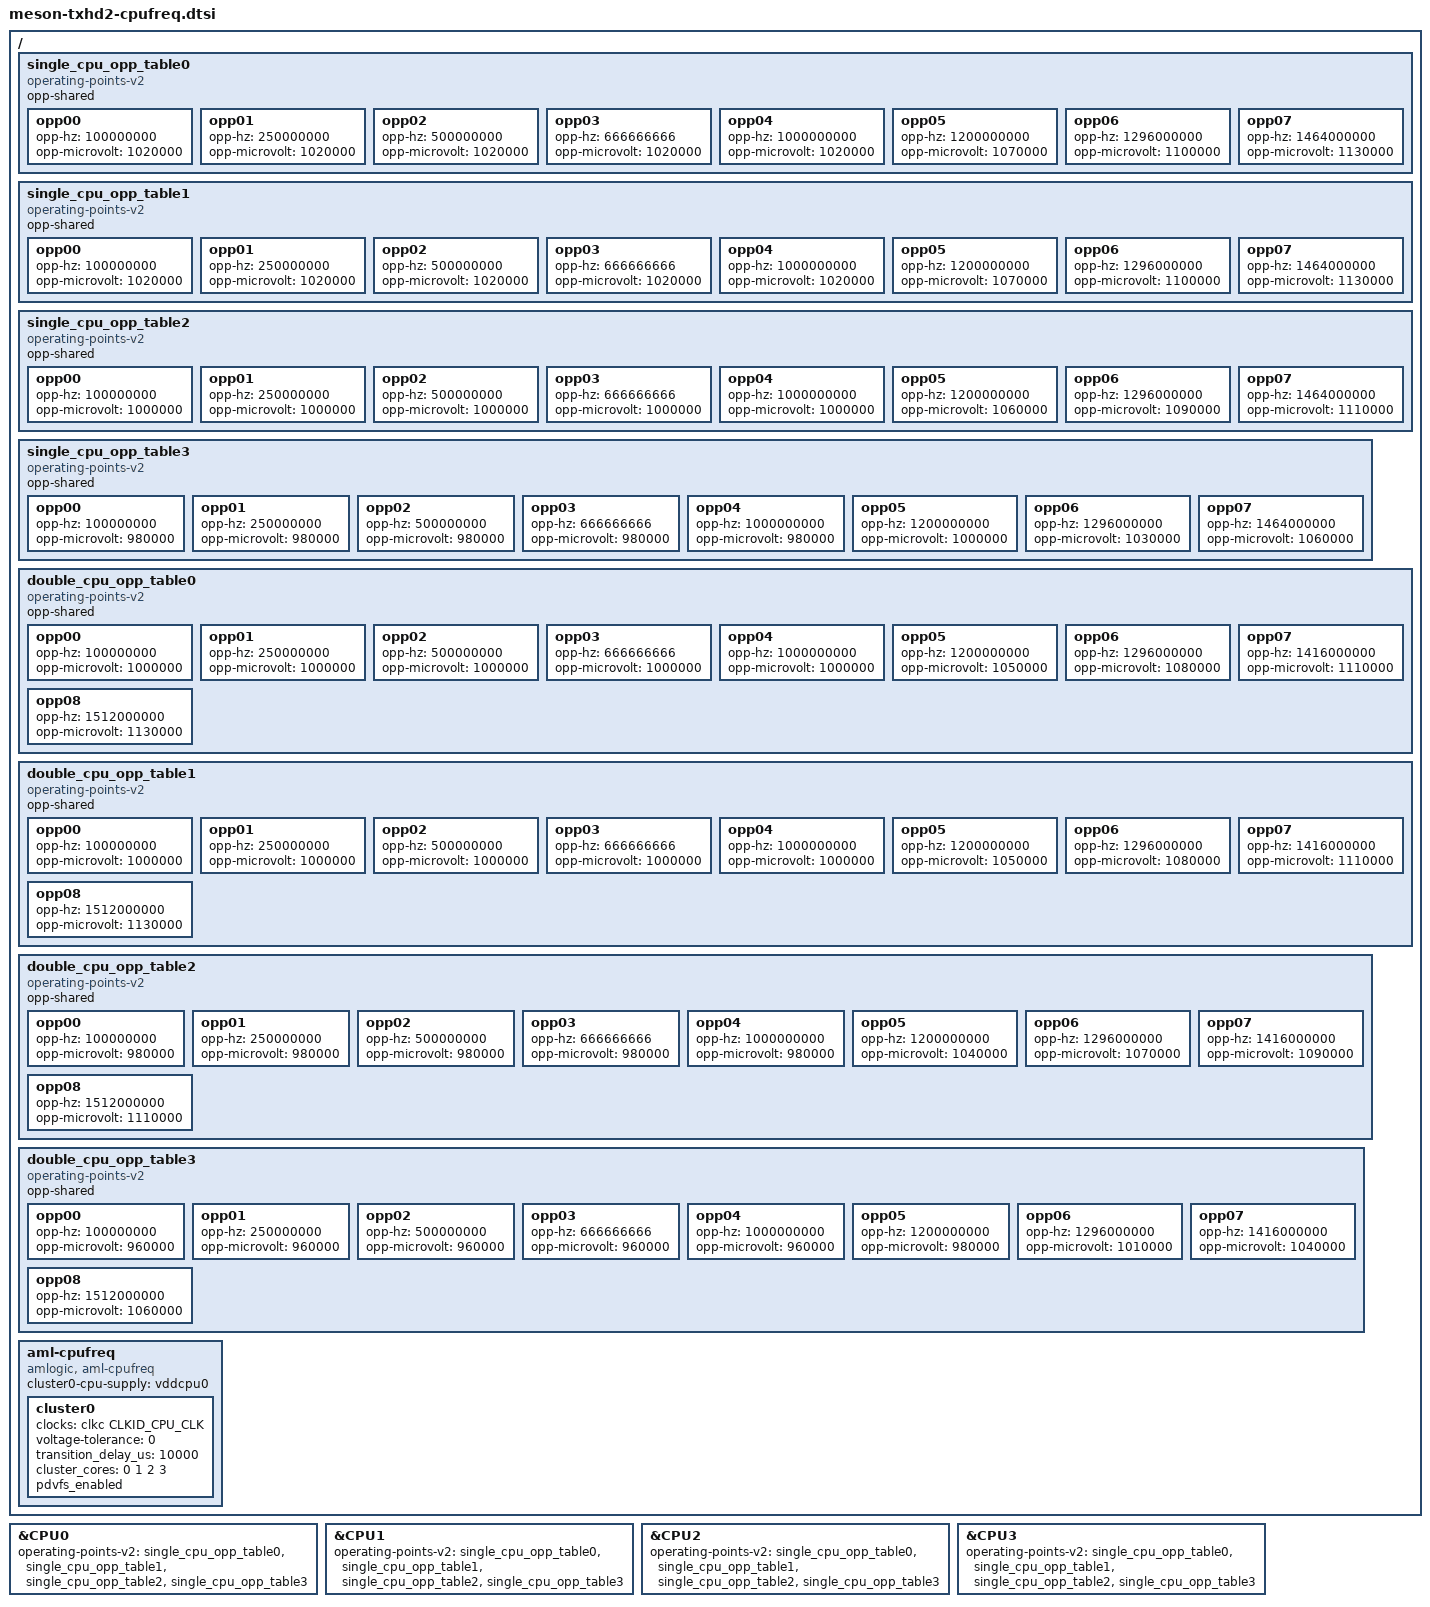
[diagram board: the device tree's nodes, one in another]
// SPDX-License-Identifier: (GPL-2.0+ OR MIT)
/*
 * Copyright (c) 2019 Amlogic, Inc. All rights reserved.
 */
/ {
	single_cpu_opp_table0: single_cpu_opp_table0 {
		compatible = "operating-points-v2";
		opp-shared;

		opp00 {
			opp-hz = /bits/ 64 <100000000>;
			opp-microvolt = <1020000>;
		};
		opp01 {
			opp-hz = /bits/ 64 <250000000>;
			opp-microvolt = <1020000>;
		};
		opp02 {
			opp-hz = /bits/ 64 <500000000>;
			opp-microvolt = <1020000>;
		};
		opp03 {
			opp-hz = /bits/ 64 <666666666>;
			opp-microvolt = <1020000>;
		};
		opp04 {
			opp-hz = /bits/ 64 <1000000000>;
			opp-microvolt = <1020000>;
		};
		opp05 {
			opp-hz = /bits/ 64 <1200000000>;
			opp-microvolt = <1070000>;
		};
		opp06 {
			opp-hz = /bits/ 64 <1296000000>;
			opp-microvolt = <1100000>;
		};
		opp07 {
			opp-hz = /bits/ 64 <1464000000>;
			opp-microvolt = <1130000>;
		};
	};

	single_cpu_opp_table1: single_cpu_opp_table1 {
		compatible = "operating-points-v2";
		opp-shared;

		opp00 {
			opp-hz = /bits/ 64 <100000000>;
			opp-microvolt = <1020000>;
		};
		opp01 {
			opp-hz = /bits/ 64 <250000000>;
			opp-microvolt = <1020000>;
		};
		opp02 {
			opp-hz = /bits/ 64 <500000000>;
			opp-microvolt = <1020000>;
		};
		opp03 {
			opp-hz = /bits/ 64 <666666666>;
			opp-microvolt = <1020000>;
		};
		opp04 {
			opp-hz = /bits/ 64 <1000000000>;
			opp-microvolt = <1020000>;
		};
		opp05 {
			opp-hz = /bits/ 64 <1200000000>;
			opp-microvolt = <1070000>;
		};
		opp06 {
			opp-hz = /bits/ 64 <1296000000>;
			opp-microvolt = <1100000>;
		};
		opp07 {
			opp-hz = /bits/ 64 <1464000000>;
			opp-microvolt = <1130000>;
		};
	};

	single_cpu_opp_table2: single_cpu_opp_table2 {
		compatible = "operating-points-v2";
		opp-shared;

		opp00 {
			opp-hz = /bits/ 64 <100000000>;
			opp-microvolt = <1000000>;
		};
		opp01 {
			opp-hz = /bits/ 64 <250000000>;
			opp-microvolt = <1000000>;
		};
		opp02 {
			opp-hz = /bits/ 64 <500000000>;
			opp-microvolt = <1000000>;
		};
		opp03 {
			opp-hz = /bits/ 64 <666666666>;
			opp-microvolt = <1000000>;
		};
		opp04 {
			opp-hz = /bits/ 64 <1000000000>;
			opp-microvolt = <1000000>;
		};
		opp05 {
			opp-hz = /bits/ 64 <1200000000>;
			opp-microvolt = <1060000>;
		};
		opp06 {
			opp-hz = /bits/ 64 <1296000000>;
			opp-microvolt = <1090000>;
		};
		opp07 {
			opp-hz = /bits/ 64 <1464000000>;
			opp-microvolt = <1110000>;
		};
	};

	single_cpu_opp_table3: single_cpu_opp_table3 {
		compatible = "operating-points-v2";
		opp-shared;

		opp00 {
			opp-hz = /bits/ 64 <100000000>;
			opp-microvolt = <980000>;
		};
		opp01 {
			opp-hz = /bits/ 64 <250000000>;
			opp-microvolt = <980000>;
		};
		opp02 {
			opp-hz = /bits/ 64 <500000000>;
			opp-microvolt = <980000>;
		};
		opp03 {
			opp-hz = /bits/ 64 <666666666>;
			opp-microvolt = <980000>;
		};
		opp04 {
			opp-hz = /bits/ 64 <1000000000>;
			opp-microvolt = <980000>;
		};
		opp05 {
			opp-hz = /bits/ 64 <1200000000>;
			opp-microvolt = <1000000>;
		};
		opp06 {
			opp-hz = /bits/ 64 <1296000000>;
			opp-microvolt = <1030000>;
		};
		opp07 {
			opp-hz = /bits/ 64 <1464000000>;
			opp-microvolt = <1060000>;
		};
	};

	double_cpu_opp_table0: double_cpu_opp_table0 {
		compatible = "operating-points-v2";
		opp-shared;

		opp00 {
			opp-hz = /bits/ 64 <100000000>;
			opp-microvolt = <1000000>;
		};
		opp01 {
			opp-hz = /bits/ 64 <250000000>;
			opp-microvolt = <1000000>;
		};
		opp02 {
			opp-hz = /bits/ 64 <500000000>;
			opp-microvolt = <1000000>;
		};
		opp03 {
			opp-hz = /bits/ 64 <666666666>;
			opp-microvolt = <1000000>;
		};
		opp04 {
			opp-hz = /bits/ 64 <1000000000>;
			opp-microvolt = <1000000>;
		};
		opp05 {
			opp-hz = /bits/ 64 <1200000000>;
			opp-microvolt = <1050000>;
		};
		opp06 {
			opp-hz = /bits/ 64 <1296000000>;
			opp-microvolt = <1080000>;
		};
		opp07 {
			opp-hz = /bits/ 64 <1416000000>;
			opp-microvolt = <1110000>;
		};
		opp08 {
			opp-hz = /bits/ 64 <1512000000>;
			opp-microvolt = <1130000>;
		};
	};

	double_cpu_opp_table1: double_cpu_opp_table1 {
		compatible = "operating-points-v2";
		opp-shared;

		opp00 {
			opp-hz = /bits/ 64 <100000000>;
			opp-microvolt = <1000000>;
		};
		opp01 {
			opp-hz = /bits/ 64 <250000000>;
			opp-microvolt = <1000000>;
		};
		opp02 {
			opp-hz = /bits/ 64 <500000000>;
			opp-microvolt = <1000000>;
		};
		opp03 {
			opp-hz = /bits/ 64 <666666666>;
			opp-microvolt = <1000000>;
		};
		opp04 {
			opp-hz = /bits/ 64 <1000000000>;
			opp-microvolt = <1000000>;
		};
		opp05 {
			opp-hz = /bits/ 64 <1200000000>;
			opp-microvolt = <1050000>;
		};
		opp06 {
			opp-hz = /bits/ 64 <1296000000>;
			opp-microvolt = <1080000>;
		};
		opp07 {
			opp-hz = /bits/ 64 <1416000000>;
			opp-microvolt = <1110000>;
		};
		opp08 {
			opp-hz = /bits/ 64 <1512000000>;
			opp-microvolt = <1130000>;
		};
	};

	double_cpu_opp_table2: double_cpu_opp_table2 {
		compatible = "operating-points-v2";
		opp-shared;

		opp00 {
			opp-hz = /bits/ 64 <100000000>;
			opp-microvolt = <980000>;
		};
		opp01 {
			opp-hz = /bits/ 64 <250000000>;
			opp-microvolt = <980000>;
		};
		opp02 {
			opp-hz = /bits/ 64 <500000000>;
			opp-microvolt = <980000>;
		};
		opp03 {
			opp-hz = /bits/ 64 <666666666>;
			opp-microvolt = <980000>;
		};
		opp04 {
			opp-hz = /bits/ 64 <1000000000>;
			opp-microvolt = <980000>;
		};
		opp05 {
			opp-hz = /bits/ 64 <1200000000>;
			opp-microvolt = <1040000>;
		};
		opp06 {
			opp-hz = /bits/ 64 <1296000000>;
			opp-microvolt = <1070000>;
		};
		opp07 {
			opp-hz = /bits/ 64 <1416000000>;
			opp-microvolt = <1090000>;
		};
		opp08 {
			opp-hz = /bits/ 64 <1512000000>;
			opp-microvolt = <1110000>;
		};
	};

	double_cpu_opp_table3: double_cpu_opp_table3 {
		compatible = "operating-points-v2";
		opp-shared;

		opp00 {
			opp-hz = /bits/ 64 <100000000>;
			opp-microvolt = <960000>;
		};
		opp01 {
			opp-hz = /bits/ 64 <250000000>;
			opp-microvolt = <960000>;
		};
		opp02 {
			opp-hz = /bits/ 64 <500000000>;
			opp-microvolt = <960000>;
		};
		opp03 {
			opp-hz = /bits/ 64 <666666666>;
			opp-microvolt = <960000>;
		};
		opp04 {
			opp-hz = /bits/ 64 <1000000000>;
			opp-microvolt = <960000>;
		};
		opp05 {
			opp-hz = /bits/ 64 <1200000000>;
			opp-microvolt = <980000>;
		};
		opp06 {
			opp-hz = /bits/ 64 <1296000000>;
			opp-microvolt = <1010000>;
		};
		opp07 {
			opp-hz = /bits/ 64 <1416000000>;
			opp-microvolt = <1040000>;
		};
		opp08 {
			opp-hz = /bits/ 64 <1512000000>;
			opp-microvolt = <1060000>;
		};
	};

	aml-cpufreq {
		compatible = "amlogic, aml-cpufreq";
		status = "okay";

		cluster0-cpu-supply = <&vddcpu0>;

		cluster0 {
			clocks = <&clkc CLKID_CPU_CLK>;
			clock-names = "cpuclk";
			voltage-tolerance = <0>;
			transition_delay_us = <10000>;
			//skip_volt_scaling;
			cluster_cores = <0 1 2 3>;
			pdvfs_enabled;
		};
	};
};/* end of / */

&CPU0 {
	operating-points-v2 = <&single_cpu_opp_table0>,
		<&single_cpu_opp_table1>,
		<&single_cpu_opp_table2>,
		<&single_cpu_opp_table3>;
};

&CPU1 {
	operating-points-v2 = <&single_cpu_opp_table0>,
		<&single_cpu_opp_table1>,
		<&single_cpu_opp_table2>,
		<&single_cpu_opp_table3>;
};

&CPU2 {
	operating-points-v2 = <&single_cpu_opp_table0>,
		<&single_cpu_opp_table1>,
		<&single_cpu_opp_table2>,
		<&single_cpu_opp_table3>;
};

&CPU3 {
	operating-points-v2 = <&single_cpu_opp_table0>,
		<&single_cpu_opp_table1>,
		<&single_cpu_opp_table2>,
		<&single_cpu_opp_table3>;
};
